# EFR32MG24A020F1536GM40 register map
Vendor: Silicon Labs; Series: EFR32; File version: B
Registers are 32-bit, read-write, reset 0x0 unless marked. A register's access mark holds for its fields unless they carry their own. Offsets are from the block's base; [hi:lo] are bit positions; {n}, {i} and the like mark numbered series; 'fields as' and 'values as' point back to an identical list.

## FRC_S — FRC_S Registers
Base 0xA8004000
Same registers: FRC_NS 0xB8004000
0x00 IPVERSION ro reset 0x3
0x04 EN
  [0] EN — Enable peripheral clock to this module
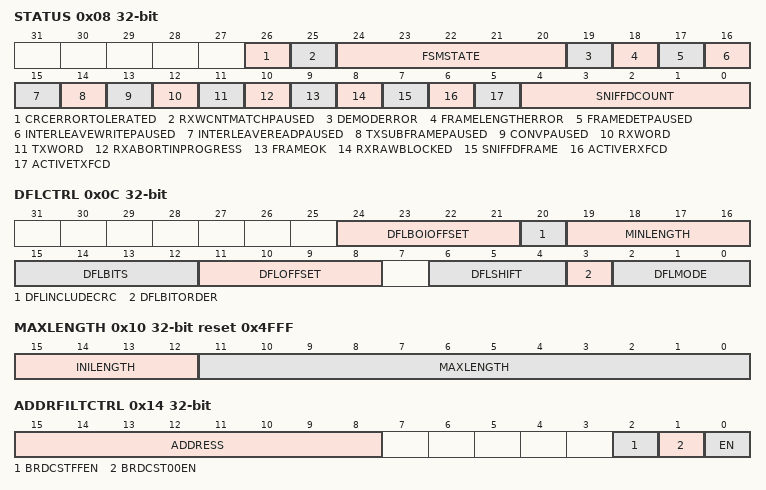
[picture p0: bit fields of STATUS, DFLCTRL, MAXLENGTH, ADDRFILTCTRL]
0x08 STATUS ro
  [26] CRCERRORTOLERATED
  [25] RXWCNTMATCHPAUSED — Nth byte received pause event active
  [24:20] FSMSTATE — FSM state status for srw_frc_interface
    0=IDLE; 1=RX_INIT; 2=RX_DATA; 3=RX_CRC; 4=RX_FCD_UPDATE; 5=RX_DISCARD; 6=RX_TRAIL; 7=RX_DONE; 8=RX_PAUSE_INIT; 9=RX_PAUSED; 10=UNDEFINED1; 11=UNDEFINED2; 12=RX_CRC_ZEROCHECK; 13=RX_SUP; 14=RX_WAITEOF; 15=UNDEFINED3; 16=TX_INIT; 17=TX_DATA; 18=TX_CRC; 19=TX_FCD_UPDATE; 20=TX_TRAIL; 21=TX_FLUSH; 22=TX_DONE; 23=TX_DONE_WAIT; 24=TX_RAW; 25=TX_PAUSEFLUSH
  [19] DEMODERROR — Demod Error in RX
  [18] FRAMELENGTHERROR — Frame Length Error for RX and TX
  [17] FRAMEDETPAUSED — Frame detected pause event active
  [16] INTERLEAVEWRITEPAUSED — Interleaver write pause event active
  [15] INTERLEAVEREADPAUSED — Interleaver read pause event active
  [14] TXSUBFRAMEPAUSED — Transmit subframe pause event active
  [13] CONVPAUSED — Convolutional coder pause event active
  [12] RXWORD — Receive Word Flag
  [11] TXWORD — Transmit Word Flag
  [10] RXABORTINPROGRESS — Receive aborted in progress status flag
  [9] FRAMEOK — Frame valid
  [8] RXRAWBLOCKED — Receiver raw trigger block is active
  [7] SNIFFDFRAME — Sniffer data frame active status
  [6] ACTIVERXFCD — Active Receive Frame Descriptor
    0=FCD2 (FCD2 is active); 1=FCD3 (FCD3 is active)
  [5] ACTIVETXFCD — Active Transmit Frame Descriptor
    0=FCD0 (FCD0 is active); 1=FCD1 (FCD1 is active)
  [4:0] SNIFFDCOUNT — Sniffer data count
0x0C DFLCTRL
  [24:21] DFLBOIOFFSET — Length Field Offset Value
  [20] DFLINCLUDECRC — Length field includes CRC values or not
    0=The CRC values are not included in the frame length; 1=The CRC values are included in the frame length
  [19:16] MINLENGTH — Minimum decoded length
  [15:12] DFLBITS — Length field number of bits
  [11:8] DFLOFFSET — Length Field Offset Value
  [6:4] DFLSHIFT — Dynamic Frame Length bitshift
  [3] DFLBITORDER — Dynamic Frame Length Bit order
    0=NORMAL (Bit ordering is defined by the BITORDER field); 1=REVERSE (Bit ordering is reversed, compared to what is defined by the BITORDER field)
  [2:0] DFLMODE — Dynamic Frame Length Mode
    0=DISABLE (Dynamic Frame Length support is disabled, and the frame length is controlled by writing directly to the FRAMELENGTH field); 1=SINGLEBYTE (Dynamic Frame Length is enabled and located in a single byte over air. This byte is loaded into the least significant byte of the extracted length field); 2=SINGLEBYTEMSB (Dynamic Frame Length is enabled and located in a single byte over air. This byte is loaded into the most significant byte of the extracted length field); 3=DUALBYTELSBFIRST (Dynamic Frame Length is enabled and located in two bytes over air, of which the least significant byte is transferred first); 4=DUALBYTEMSBFIRST (Dynamic Frame Length is enabled and located in two bytes over air, of which the most significant byte is transferred first); 5=INFINITE (Dynamic Frame Length support is disabled, and infinite frame lengths are transmitted and received. RXABORT may be used to abort active receive operations, while the TXDIS command (available in the RAC) may be used to abort active transmit operations.); 6=BLOCKERROR (In transmit mode, the frame length must be written directly to the FRAMELENGTH field. In receive mode, data will be received until a block decoding error is found.)
0x10 MAXLENGTH reset 0x4FFF
  [15:12] INILENGTH — Initial Frame Length Value
  [11:0] MAXLENGTH — Max Frame Length Value
0x14 ADDRFILTCTRL
  [15:8] ADDRESS
  [2] BRDCSTFFEN — Broadcast Address 0xFF Enable
  [1] BRDCST00EN — Broadcast Address 0x00 Enable
  [0] EN — Address Filter Enable
0x18 DATABUFFER
  [7:0] DATABUFFER — Frame Controller data buffer
0x1C WCNT ro
  [11:0] WCNT — Word Counter Value
0x20 WCNTCMP0
  [11:0] FRAMELENGTH — Word Counter Frame Length Value
0x24 WCNTCMP1
  [11:0] LENGTHFIELDLOC — Length field location
0x28 WCNTCMP2
  [11:0] ADDRFIELDLOC — Address field location
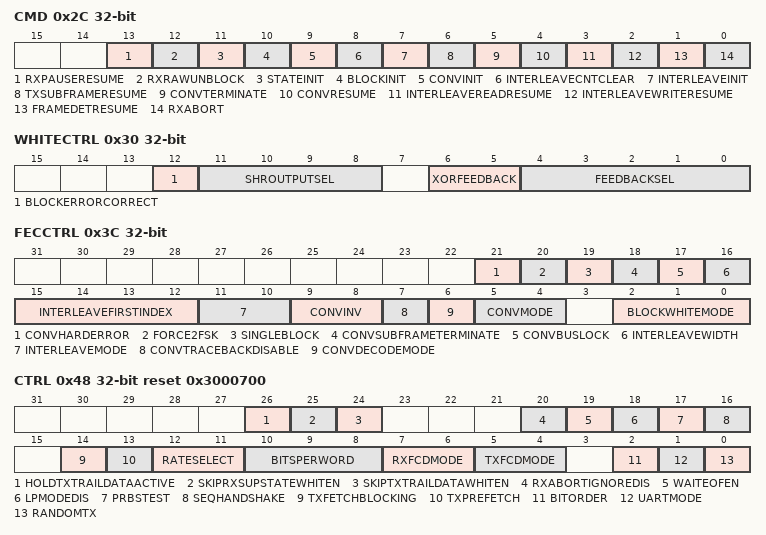
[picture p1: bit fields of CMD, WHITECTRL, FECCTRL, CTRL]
0x2C CMD wo
  [13] RXPAUSERESUME — RX pause on nth byte resume
  [12] RXRAWUNBLOCK — Clear RXRAWBLOCKED status flag
  [11] STATEINIT — FRC State initialize
  [10] BLOCKINIT — Block coder initialize
  [9] CONVINIT — Convolutional coder initialize
  [8] INTERLEAVECNTCLEAR — Interleaver counter clear
  [7] INTERLEAVEINIT — Interleaver initialization
  [6] TXSUBFRAMERESUME
  [5] CONVTERMINATE — Convolutional coder termination
  [4] CONVRESUME — Convolutional coder resume
  [3] INTERLEAVEREADRESUME — Interleaver read resume
  [2] INTERLEAVEWRITERESUME — Interleaver write resume
  [1] FRAMEDETRESUME
  [0] RXABORT
0x30 WHITECTRL
  [12] BLOCKERRORCORRECT — Block Errors Correction enable
    0=Block decoding errors are not corrected, only the BLOCKERR interrupt is set on detection; 1=Block decoding errors are attempted corrected by memory lookup tables. The BLOCKERR interrupt is also set on error detection.
  [11:8] SHROUTPUTSEL — Shift Register Output Selector
  [6:5] XORFEEDBACK — LFSR Feedback XOR setting
    0=DIRECT (The signal defined by FEEDBACKSEL is used directly as Feedback.); 1=XOR (The signal defined by FEEDBACKSEL is XOR'ed with bit 15, and the result is used as Feedback); 2=ZERO (Feedback is set to 0)
  [4:0] FEEDBACKSEL — LFSR Feedback selector
    {v}=BIT{v} (Select bit {v} as feedback) (v=0..15); 16=INPUT (Select data input as feedback); 17=ZERO (Select zero as feedback); 18=ONE (Select one as feedback); 19=TXLASTWORD (In transmit mode, the feedback is one during the last transmit word and zero otherwise. In receive mode, the feedback is always zero.)
0x34 WHITEPOLY
  [15:0] POLY — Whitener Polynomial
0x38 WHITEINIT
  [15:0] WHITEINIT — Whitener Initial Value
0x3C FECCTRL
  [21] CONVHARDERROR — Enable convolutional decoding hard error
    0=Convolutional hard error decoding is disabled; 1=Convolutional hard error decoding is enabled
  [20] FORCE2FSK — Force use of 2-FSK
  [19] SINGLEBLOCK — Single block code per frame
  [18] CONVSUBFRAMETERMINATE — Enable trellis termination for subframes
    0=Trellis termination is applied at the end of the frame; 1=Trellis termination is applied at the end of each subframe and at the end of the frame
  [17] CONVBUSLOCK — Convolutional decoding bus lock
  [16] INTERLEAVEWIDTH — Interleave symbol width.
    0=ONE (Each interleaver element consists of one RF symbol); 1=TWO (Each interleaver element consists of two RF symbols)
  [15:12] INTERLEAVEFIRSTINDEX — 4-bit index of the first interleaver
  [11:10] INTERLEAVEMODE — Interleaver mode.
    0=DISABLE (Interleaving is disabled); 1=ENABLE (Interleaving is enabled); 2=RXBUFFER (No symbol interleaving is performed, but the interleaver data storage is used as a data buffer in receive mode. This may, for instance, be used for receiver pause functionality.); 3=RXTXBUFFER (No symbol interleaving is performed, but the interleaver data storage is used as a data buffer in receive and transmit mode. This may, for instance, be used for receiver and transmitter pause functionality.)
  [9:8] CONVINV — Convolutional code symbol inversion
  [7] CONVTRACEBACKDISABLE — Convolutional traceback disabling
    0=Traceback history is enabled, and convolutional decoding will use RAM to store state information. In receive mode, output from convolutional decoding will be generated after the traceback history has reached a certain level.; 1=Traceback history is disabled, and convolutional decoding will not use RAM to store state information. No trellis termination sequence will be automatically appended to the transmit data. In receive mode, output from convolutional decoding will be generated after every state transition. This will not provide any convolutional decoding gain, but can be used to decode very simple codes without using any RAM memory.
  [6] CONVDECODEMODE — Convolutional decoding mode setting.
    0=SOFT (Use soft decision convolutional decoding, recommended in most cases.); 1=HARD (Use hard decision convolutional decoding.)
  [5:4] CONVMODE — Convolutional Encoder / Decoder mode.
    0=DISABLE (Convolutional encoding / decoding is disabled); 1=CONVOLUTIONAL (Normal convolutional encoding / decoding is enabled); 2=REPEAT (Repeat-mode convolutional encoding / decoding is enabled)
  [2:0] BLOCKWHITEMODE — Block Coder Whitener Mode
    0=DIRECT (The input data is passed directly to the output without any other operations.); 1=WHITE (Data is whitened in TX and de-whitened in RX with the whitener feedback register updated every bit period.); 2=BYTEWHITE (Data is whitened in TX and de-whitened in RX with the whitener feedback register updated every byte period, recommended only for compatibility purposes.); 3=INTERLEAVEDWHITE0 (Data is whitened in TX after symbol interleaving and de-whitened in RX before symbol de-interleaving.); 4=INTERLEAVEDWHITE1 (Data is whitened in TX after symbol interleaving and de-whitened in RX before symbol de-interleaving. The first 16 (if INTERLEAVEWIDTH is 0) or 32 (if INTERLEAVEWIDTH is 1) RF symbols are not whitened or de-whitened.); 5=BLOCKCODEINSERT (Parity bits are added in TX and checked and removed in RX to perform block coding forward error correction (FEC). In transmit mode, the block encoder will insert parity bits between the bit stream provided from the transmit buffer. In receive mode, the block decoder will remove parity bits and they will not further be provided to the receive buffer.); 6=BLOCKCODEREPLACE (Parity bits are added in TX and checked and removed in RX to perform block coding forward error correction (FEC). In transmit mode, the block encoder will replace bits provided by the transmit buffer with parity bits. In receive mode, the block decoder will output both data bits and parity bits to the receive buffer.); 7=BLOCKLOOKUP (A lookup table is used to implement table lookup block coding in TX, and table lookup block decoding in RX.)
0x40 BLOCKRAMADDR reset 0x4000
  [31:2] BLOCKRAMADDR — Block decoding RAM address
0x44 CONVRAMADDR reset 0x4000
  [31:2] CONVRAMADDR — Convolutional decoding RAM address
0x48 CTRL reset 0x3000700
  [26] HOLDTXTRAILDATAACTIVE — Defeat bit to hold txtraildata active
  [25] SKIPRXSUPSTATEWHITEN — RX Supplemental Data Skip Whitening
  [24] SKIPTXTRAILDATAWHITEN — TX Trail Data Skip Whitening
  [20] RXABORTIGNOREDIS — Disable ignoring CMD_RXABORT
  [19] WAITEOFEN — Enable STATE_TX_WAITEOF
  [18] LPMODEDIS — Disable FRC low power
  [17] PRBSTEST — Pseudo-Random Bit Sequence Testmode
  [16] SEQHANDSHAKE — Sequencer data handshake
    0=The sequencer may read transmit or read data through the FRCRD command, but it will not wait for the sequencer to do so before proceeding to parse transmit or receive data; 1=The frame controller will require that the sequencer program uses the FRCRD command to read both transmit and receive data which the frame controller stores in the DATABUFFER register. If data is not read with this field set, the overflow (RXOF) or underflow (TXUF) will be set.
  [14] TXFETCHBLOCKING — Transmit fetch data blocking
  [13] TXPREFETCH — Transmit prefetch data
    0=The frame controller will start preparing transmit data when entering the TX state. This setting may be used in most cases.; 1=The frame controller will start preparing transmit data already in the TXWARM, RX2TX or TX2TX state. This setting must be used to avoid transmit underflow in the cases where no preamble or frame synchronization is inserted by the modulator (i.e. typically when the MODEM control fields TXBASES is zero and SYNCDATA is set).
  [12:11] RATESELECT — MODEM rate select
  [10:8] BITSPERWORD — Bits Per Word, for first word in a frame
  [7:6] RXFCDMODE — RX Frame Control Descriptor Mode
    0=FCDMODE0 (FCD2 is reloaded when SCNT reaches 0); 1=FCDMODE1 (Use FCD2 for the first sub-frame, then switching between FCD2 and FCD3 for following sub-frames); 2=FCDMODE2 (Use FCD2 for the first sub-frame, then FCD3 is used for all following sub-frames); 3=FCDMODE3 (Use alternating FCD2 / FCD3 for each complete frame)
  [5:4] TXFCDMODE — TX Frame Control Descriptor Mode
    0=FCDMODE0 (FCD0 is reloaded when SCNT reaches 0); 1=FCDMODE1 (Use FCD0 for the first sub-frame, then switching between FCD0 and FCD1 for following sub-frames); 2=FCDMODE2 (Use FCD0 for the first sub-frame, then FCD1 is used for all following sub-frames); 3=FCDMODE3 (Use alternating FCD0 / FCD1 for each complete frame)
  [2] BITORDER — Data Bit Order.
    0=LSBFIRST (Least Significant bit in each word is sent/received first.); 1=MSBFIRST (Most Significant bit in each word is sent/received first.)
  [1] UARTMODE — Data Uart Mode
  [0] RANDOMTX — Random TX Mode
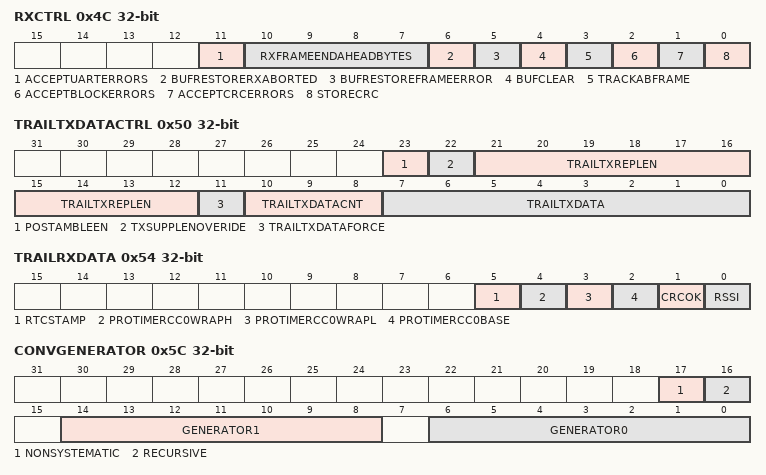
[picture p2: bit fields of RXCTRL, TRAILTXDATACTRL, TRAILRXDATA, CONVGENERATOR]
0x4C RXCTRL
  [11] ACCEPTUARTERRORS — Accept UART Start/Stop bit Errors.
  [10:7] RXFRAMEENDAHEADBYTES — RX frame almost end of packet timing
  [6] BUFRESTORERXABORTED — Buffer restore on RXABORTED
  [5] BUFRESTOREFRAMEERROR — Buffer restore on frame error
  [4] BUFCLEAR — Buffer Clear
  [3] TRACKABFRAME — Track Aborted RX Frame
    0=When a frame abort is triggered, the frame reception is immediately aborted, the RXABORTED interrupt flag is set, and the receiver may start searching for a new frame; 1=When a frame abort is triggered, the receiver is still enabled for the duration of the frame (as defined by the frame length), but no data output is generated. Only when the complete frame is received, the RXABORTED interrupt flag is set and a new frame reception may begin. This mode may, for instance, be used to avoid finding a new FRAMEDET event inside the payload data of a discarded frame.
  [2] ACCEPTBLOCKERRORS — Accept Block Decoding Errors.
    0=REJECT (Frame reception will be stopped when a block decoding error is found.); 1=ACCEPT (Frame reception will continue even in the case of a block decoding error.)
  [1] ACCEPTCRCERRORS
    0=REJECT (Frames with one or more detected CRC errors will be cleared from the receiver buffer.); 1=ACCEPT (Frames will always be written to the receive buffer, regardless of CRC errors.)
  [0] STORECRC — Store CRC value.
0x50 TRAILTXDATACTRL
  [23] POSTAMBLEEN — WMBUS T mode postamble enable
  [22] TXSUPPLENOVERIDE — TX Sup Len Override
  [21:12] TRAILTXREPLEN — Trailing Data Repeat Length
  [11] TRAILTXDATAFORCE — Force trailing TX data insertion
    0=Trailing data in transmit is only applied in order to fill up an integer number of block coding and interleaver buffers. If block coding and interleaving is not used, no trailing data is transmitted.; 1=The number of bits defined by TRAILTXDATACNT is always appended to the transmit data, in addition to the necessary bits to fill up an integer number of block coding and interleaver buffers
  [10:8] TRAILTXDATACNT — Trailing data bit count
  [7:0] TRAILTXDATA — Trailing Data value
0x54 TRAILRXDATA
  [5] RTCSTAMP — RTCC Time Stamp
  [4] PROTIMERCC0WRAPH — PROTIMER Capture Compare channel 0 WrapH
  [3] PROTIMERCC0WRAPL — PROTIMER Capture Compare channel 0 WrapL
  [2] PROTIMERCC0BASE — PROTIMER Capture Compare channel 0 Base
  [1] CRCOK — Append CRC OK Indicator
  [0] RSSI — Append RSSI
0x58 SCNT ro
  [7:0] SCNT — Sub-Frame Counter Value
0x5C CONVGENERATOR
  [17] NONSYSTEMATIC — Non systematic recursive code
    0=The recursive code is systematic; 1=The recursive code is not systematic
  [16] RECURSIVE — Convolutional encoding
    0=Non-recursive convolutional coding is used; 1=Recursive convolutional coding is used
  [14:8] GENERATOR1 — Output 1 Generator Polynomial
  [6:0] GENERATOR0 — Output 0 Generator Polynomial
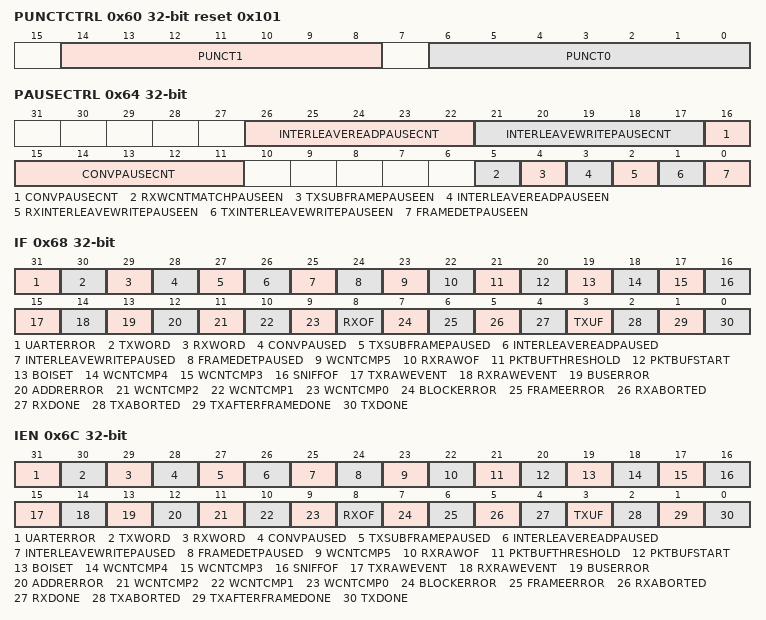
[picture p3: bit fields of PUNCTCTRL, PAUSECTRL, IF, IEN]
0x60 PUNCTCTRL reset 0x101
  [14:8] PUNCT1 — Puncturing Matrix Row for Output 1
  [6:0] PUNCT0 — Puncturing Matrix Row for Output 0
0x64 PAUSECTRL
  [26:22] INTERLEAVEREADPAUSECNT — Interleaver read pause count
  [21:17] INTERLEAVEWRITEPAUSECNT — Interleaver write pause count
  [16:11] CONVPAUSECNT — Convolutional decoder pause setting
  [5] RXWCNTMATCHPAUSEEN — Receive wcnt match pause enable
  [4] TXSUBFRAMEPAUSEEN — Transmit subframe pause enable
  [3] INTERLEAVEREADPAUSEEN — Interleaver read pause enable
  [2] RXINTERLEAVEWRITEPAUSEEN — Receive interleaver write pause enable
  [1] TXINTERLEAVEWRITEPAUSEEN — Transmit interleaver write pause enable
  [0] FRAMEDETPAUSEEN — Frame detect pause enable
0x68 IF
  [31] UARTERROR — Uart Error Interrupt Flag
  [30] TXWORD — Transmit Word Interrupt Flag
  [29] RXWORD — Receive Word Interrupt Flag
  [28] CONVPAUSED — Convolutional coder pause event active
  [27] TXSUBFRAMEPAUSED — Transmit subframe pause event active
  [26] INTERLEAVEREADPAUSED — Interleaver read pause event active
  [25] INTERLEAVEWRITEPAUSED — Interleaver write pause event active
  [24] FRAMEDETPAUSED — Frame detected pause event active
  [23] WCNTCMP5 — Word Counter Compare 5 Event
  [22] RXRAWOF — RX raw FIFO overflow
  [21] PKTBUFTHRESHOLD — Packet Buffer Threshold
  [20] PKTBUFSTART — Packet Buffer Start
  [19] BOISET
  [18] WCNTCMP4 — Word Counter Compare 4 Event
  [17] WCNTCMP3 — Word Counter Compare 3 Event
  [16] SNIFFOF — Data sniffer overflow
  [15] TXRAWEVENT — Transmit raw data event
  [14] RXRAWEVENT — Receiver raw data event
  [13] BUSERROR — A bus error event occurred
  [12] ADDRERROR — Receive address error event
  [11] WCNTCMP2 — Word Counter Compare 2 Event
  [10] WCNTCMP1 — Word Counter Compare 1 Event
  [9] WCNTCMP0 — Word Counter Compare 0 Event
  [8] RXOF — Receive Overflow Interrupt Flag
  [7] BLOCKERROR — Block Error Interrupt Flag
  [6] FRAMEERROR — Frame Error Interrupt Flag
  [5] RXABORTED — RX Aborted Interrupt Flag
  [4] RXDONE — RX Done Interrupt Flag
  [3] TXUF — Transmit Underflow Interrupt Flag
  [2] TXABORTED — Transmit Aborted Interrupt Flag
  [1] TXAFTERFRAMEDONE — TX after frame Done Interrupt Flag
  [0] TXDONE — TX Done Interrupt Flag
0x6C IEN
  [31] UARTERROR — UART Error Interrupt Enable
  [30] TXWORD — Transmit Word Interrupt Enable
  [29] RXWORD — Receive Word Interrupt Enable
  [28] CONVPAUSED — Convolutional coder pause event enable
  [27] TXSUBFRAMEPAUSED — Transmit subframe pause event enable
  [26] INTERLEAVEREADPAUSED — Interleaver read pause event enable
  [25] INTERLEAVEWRITEPAUSED — Interleaver write pause event enable
  [24] FRAMEDETPAUSED — Frame detected pause event enable
  [23] WCNTCMP5 — Word Counter Compare 5 Enable
  [22] RXRAWOF — RXRAWOF Enable
  [21] PKTBUFTHRESHOLD — PKTBUFTHRESHOLD Enable
  [20] PKTBUFSTART — PKTBUFSTART Enable
  [19] BOISET
  [18] WCNTCMP4 — Word Counter Compare 4 Enable
  [17] WCNTCMP3 — Word Counter Compare 3 Enable
  [16] SNIFFOF — Data sniffer overflow enable
  [15] TXRAWEVENT — Transmit raw data enable
  [14] RXRAWEVENT — Receiver raw data enable
  [13] BUSERROR — Bus error enable
  [12] ADDRERROR — Receive address error enable
  [11] WCNTCMP2 — Word Counter Compare 2 Enable
  [10] WCNTCMP1 — Word Counter Compare 1 Enable
  [9] WCNTCMP0 — Word Counter Compare 0 Enable
  [8] RXOF — Receive Overflow Interrupt Enable
  [7] BLOCKERROR — Block Error Interrupt Enable
  [6] FRAMEERROR — Frame Error Interrupt Enable
  [5] RXABORTED — RX Aborted Interrupt Enable
  [4] RXDONE — RX Done Interrupt Enable
  [3] TXUF — Transmit Underflow Interrupt Enable
  [2] TXABORTED — Transmit Aborted Interrupt Enable
  [1] TXAFTERFRAMEDONE — TX after frame Done Interrupt Enable
  [0] TXDONE — TX Done Interrupt Enable
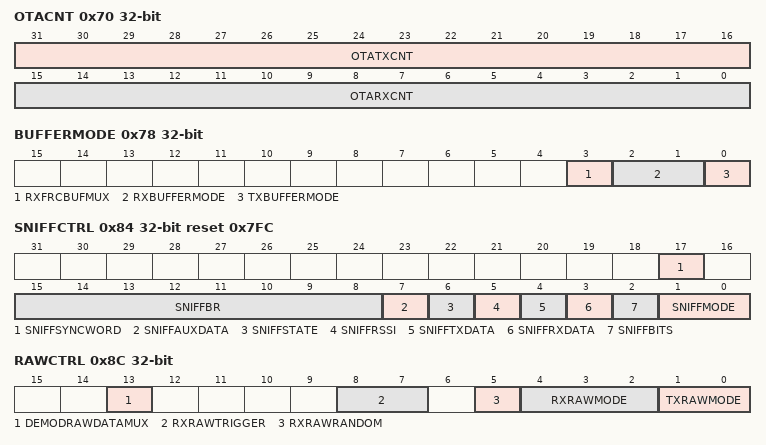
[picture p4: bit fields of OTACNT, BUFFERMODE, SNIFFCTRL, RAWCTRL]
0x70 OTACNT ro
  [31:16] OTATXCNT — OTA TX bit counter
  [15:0] OTARXCNT — OTA RX bit counter
0x78 BUFFERMODE
  [3] RXFRCBUFMUX — RX FRC Buffer Mux
  [2:1] RXBUFFERMODE — Receive Buffer Mode
    0=BUFC (The Frame Controller write data to the Buffer Controller (BUFC) in receive mode.); 1=REGISTER (The Frame Controller does not write data to the Buffer Controller in receive mode. Instead, data must be read from the DATABUFFER register when the RXWORD interrupt flag is set.); 2=DISABLE (The Frame Controller will not output demodulated data. This mode can, for instance, be used together with storing RAW frame data.)
  [0] TXBUFFERMODE — Transmit Buffer Mode
    0=BUFC (The Frame Controller fetches data from the Buffer Controller (BUFC) in transmit mode.); 1=REGISTER (The Frame Controller does not fetch data from the Buffer Controller in transmit mode. Instead, data must be written to the DATABUFFER register when the TXWORD interrupt flag is set.)
0x84 SNIFFCTRL reset 0x7FC
  [17] SNIFFSYNCWORD — Sniffer baudrate setting
  [15:8] SNIFFBR — Sniffer baudrate setting
  [7] SNIFFAUXDATA — Enable sniffing of auxiliary data
  [6] SNIFFSTATE — Enable sniffing of state information
  [5] SNIFFRSSI — Enable sniffing of RSSI
  [4] SNIFFTXDATA — Enable sniffing of transmitted data.
  [3] SNIFFRXDATA — Enable sniffing of received data.
  [2] SNIFFBITS — Data sniff data bits
    0=EIGHT (Each sniffer output word contains 8 data bits); 1=NINE (Each sniffer output word contains 9 data bits)
  [1:0] SNIFFMODE — Data Sniff Mode
    0=OFF (FRC Packet Sniffer mode is disabled); 1=UART (UART encoded data is transmitted on the DOUT pin.); 2=SPI (SPI data is transmitted on the DOUT pin and a data clock is output to the DCLK pin.)
0x88 AUXDATA wo
  [8:0] AUXDATA — Auxiliary sniffer data output
0x8C RAWCTRL
  [13] DEMODRAWDATAMUX — Raw data mux control
    0=DEMODRAWDATASEL (RAW data is selected using modem register DEMODRAWDATASEL.); 1=DEMODRAWDATASEL2 (RAW data is selected using modem register DEMODRAWDATASEL2.)
  [8:7] RXRAWTRIGGER — Receiver raw data trigger setting
    0=IMMEDIATE (RAW data storage is triggered immediately when demodulator is enabled.); 1=PRS (RAW data storage is triggered by the selected RXRAWPRSSEL PRS channel.); 2=INTERNALSIG (RAW data storage is triggered by an internal signal)
  [5] RXRAWRANDOM — Receive raw data random number generator
  [4:2] RXRAWMODE — Receiver raw data mode
    0=DISABLE (RAW receive mode is disabled); 1=SINGLEITEM (RAW receive mode is enabled, fetching a single item which is stored in the RXRAWDATA register. A new item is fetched when the RXRAWBLOCKED flag is cleared. In this mode, the flag is cleared automatically when RXRAWDATA is read.); 2=SINGLEBUFFER (RAW receive mode is enabled, fetching multiple items which are stored to RAM. The RXRAWBLOCKED flag must be cleared in order to start raw data reception.); 3=SINGLEBUFFERFRAME (This mode is identical to the SINGLEBUFFER mode, except that the FRC will treat the end of the filled buffer as the end of a frame reception (i.e. also trigger the RXDONE interrupt and signal to the RAC that frame reception is complete.)); 4=REPEATBUFFER (RAW receive mode is enabled, fetching multiple items which are stored to RAM. The RXRAWBLOCKED flag must be cleared in order to start raw data reception.)
  [1:0] TXRAWMODE — Transmitter raw data mode
    0=DISABLE (RAW transmit mode is disabled); 1=SINGLEBUFFER (RAW transmit mode is enabled, transmitting the configured raw data (fetched from RAM) once before transmit is completed.); 2=REPEATBUFFER (RAW transmit mode is enabled, transmitting the configured raw data (fetched from RAM) repeatedly until the transmitter is disabled.)
0x90 RXRAWDATA ro
  [31:0] RXRAWDATA — Receiver RAW data register
0x94 PAUSEDATA ro
  [31:0] PAUSEDATA — Receiver pause data register
0x98 LIKELYCONVSTATE ro
  [5:0] LIKELYCONVSTATE — Most likely convolutional decoder state
0x9C INTELEMENTNEXT ro
  [7:0] INTELEMENTNEXT — Interleaver element value
0xA0 INTWRITEPOINT
  [4:0] INTWRITEPOINT — Interleaver buffer write pointer
0xA4 INTREADPOINT
  [4:0] INTREADPOINT — Interleaver buffer read pointer
0xA8 AUTOCG
  [15:0] AUTOCGEN — Automatic clock gate enable
0xAC CGCLKSTOP
  [15:0] FORCEOFF
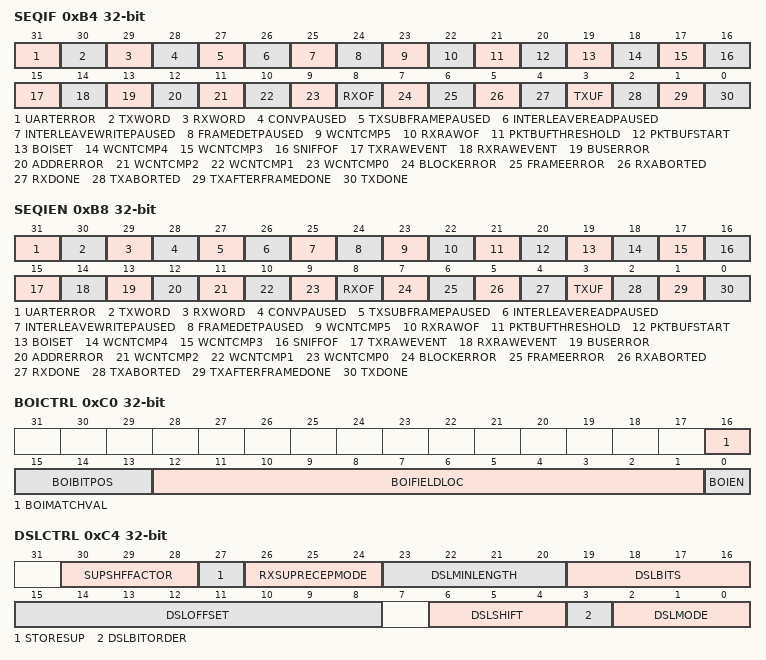
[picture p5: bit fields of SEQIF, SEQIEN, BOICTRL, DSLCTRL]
0xB4 SEQIF
  [31] UARTERROR — Uart Error Interrupt Flag
  [30] TXWORD — Transmit Word Interrupt Flag
  [29] RXWORD — Receive Word Interrupt Flag
  [28] CONVPAUSED — Convolutional coder pause event active
  [27] TXSUBFRAMEPAUSED — Transmit subframe pause event active
  [26] INTERLEAVEREADPAUSED — Interleaver read pause event active
  [25] INTERLEAVEWRITEPAUSED — Interleaver write pause event active
  [24] FRAMEDETPAUSED — Frame detected pause event active
  [23] WCNTCMP5 — Word Counter Compare 5 Event
  [22] RXRAWOF — RX raw FIFO overflow
  [21] PKTBUFTHRESHOLD — Packet Buffer Threshold
  [20] PKTBUFSTART — Packet Buffer Start
  [19] BOISET — BOISET Event
  [18] WCNTCMP4 — Word Counter Compare 4 Event
  [17] WCNTCMP3 — Word Counter Compare 3 Event
  [16] SNIFFOF — Data sniffer overflow
  [15] TXRAWEVENT — Transmit raw data event
  [14] RXRAWEVENT — Receiver raw data event
  [13] BUSERROR — A bus error event occurred
  [12] ADDRERROR — Receive address error event
  [11] WCNTCMP2 — Word Counter Compare 2 Event
  [10] WCNTCMP1 — Word Counter Compare 1 Event
  [9] WCNTCMP0 — Word Counter Compare 0 Event
  [8] RXOF — Receive Overflow Interrupt Flag
  [7] BLOCKERROR — Block Error Interrupt Flag
  [6] FRAMEERROR — Frame Error Interrupt Flag
  [5] RXABORTED — RX Aborted Interrupt Flag
  [4] RXDONE — RX Done Interrupt Flag
  [3] TXUF — Transmit Underflow Interrupt Flag
  [2] TXABORTED — Transmit Aborted Interrupt Flag
  [1] TXAFTERFRAMEDONE — TX after frame Done Interrupt Flag
  [0] TXDONE — TX Done Interrupt Flag
0xB8 SEQIEN
  [31] UARTERROR — UART Error Interrupt Enable
  [30] TXWORD — Transmit Word Interrupt Enable
  [29] RXWORD — Receive Word Interrupt Enable
  [28] CONVPAUSED — Convolutional coder pause event enable
  [27] TXSUBFRAMEPAUSED — Transmit subframe pause event enable
  [26] INTERLEAVEREADPAUSED — Interleaver read pause event enable
  [25] INTERLEAVEWRITEPAUSED — Interleaver write pause event enable
  [24] FRAMEDETPAUSED — Frame detected pause event enable
  [23] WCNTCMP5 — Word Counter Compare 5 Enable
  [22] RXRAWOF — RXRAWOF Enable
  [21] PKTBUFTHRESHOLD — PKTBUFTHRESHOLD Enable
  [20] PKTBUFSTART — PKTBUFSTART Enable
  [19] BOISET — Word Counter Compare 2 Enable
  [18] WCNTCMP4 — Word Counter Compare 4 Enable
  [17] WCNTCMP3 — Word Counter Compare 3 Enable
  [16] SNIFFOF — Data sniffer overflow enable
  [15] TXRAWEVENT — Transmit raw data enable
  [14] RXRAWEVENT — Receiver raw data enable
  [13] BUSERROR — Bus error enable
  [12] ADDRERROR — Receive address error enable
  [11] WCNTCMP2 — Word Counter Compare 2 Enable
  [10] WCNTCMP1 — Word Counter Compare 1 Enable
  [9] WCNTCMP0 — Word Counter Compare 0 Enable
  [8] RXOF — Receive Overflow Interrupt Enable
  [7] BLOCKERROR — Block Error Interrupt Enable
  [6] FRAMEERROR — Frame Error Interrupt Enable
  [5] RXABORTED — RX Aborted Interrupt Enable
  [4] RXDONE — RX Done Interrupt Enable
  [3] TXUF — Transmit Underflow Interrupt Enable
  [2] TXABORTED — Transmit Aborted Interrupt Enable
  [1] TXAFTERFRAMEDONE — TX after frame Done Interrupt Enable
  [0] TXDONE — TX Done Interrupt Enable
0xBC WCNTCMP3
  [11:0] SUPPLENFIELDLOC — Sup Length field location
0xC0 BOICTRL
  [16] BOIMATCHVAL — BOI match value
  [15:13] BOIBITPOS — BOI bit position
  [12:1] BOIFIELDLOC — BOI field location
  [0] BOIEN
0xC4 DSLCTRL
  [30:28] SUPSHFFACTOR — Supp Shift factor
  [27] STORESUP — Store SUPP in BUFC
  [26:24] RXSUPRECEPMODE — RX Supplement Reception Mode
    0=NOSUP (Do not receive SUP); 1=BOIDSLBASED (Receive SUP based on BOI and fetch SUPLEN from DSL setting); 2=BOIFIXEDSLBASED (Receive SUP based on BOI and fetch SUPLEN from WCNTCMP4); 3=DSLBASED (Receive SUP based irrespective of BOI and fetch SUPLEN from DSL setting); 4=FIXEDSLBASED (Receive SUP based irrespective of BOI and fetch SUPLEN from WCNTCMP4 setting)
  [23:20] DSLMINLENGTH — Minimum decoded length
  [19:16] DSLBITS — Length field number of bits
  [15:8] DSLOFFSET — Length Field Offset Value
  [6:4] DSLSHIFT — Dynamic Frame Length bitshift
  [3] DSLBITORDER — Dynamic Frame Length Bit order
    values as DFLCTRL.DFLBITORDER
  [2:0] DSLMODE — Dynamic Frame Length Mode
    values as DFLCTRL.DFLMODE
0xC8 WCNTCMP4
  [11:0] SUPPLENGTH — Supp Length Value
0xCC WCNTCMP5
  [11:0] RXPAUSELOC — RX pause location
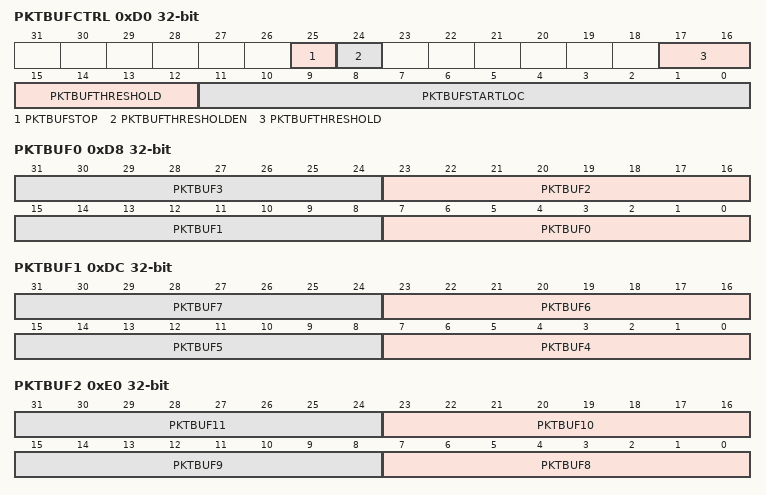
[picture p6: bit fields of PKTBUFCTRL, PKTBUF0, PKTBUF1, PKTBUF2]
0xD0 PKTBUFCTRL
  [25] PKTBUFSTOP wo — Packet Buffer stop receiving command
  [24] PKTBUFTHRESHOLDEN — Packet Buffer Threshold Enable
  [17:12] PKTBUFTHRESHOLD — Packet Buffer Threshold
  [11:0] PKTBUFSTARTLOC — Packet Buffer Start Address
0xD4 PKTBUFSTATUS ro
  [5:0] PKTBUFCOUNT — Packet Buffer Count
0xD8 PKTBUF0 ro
  [8n+7:8n] PKTBUF{n} (n=0..3) — Packet Capture Buffer
0xDC PKTBUF1 ro
  [8n-25:8n-32] PKTBUF{n} (n=4..7) — Packet Capture Buffer
0xE0 PKTBUF2 ro
  [8n-57:8n-64] PKTBUF{n} (n=8..11) — Packet Capture Buffer
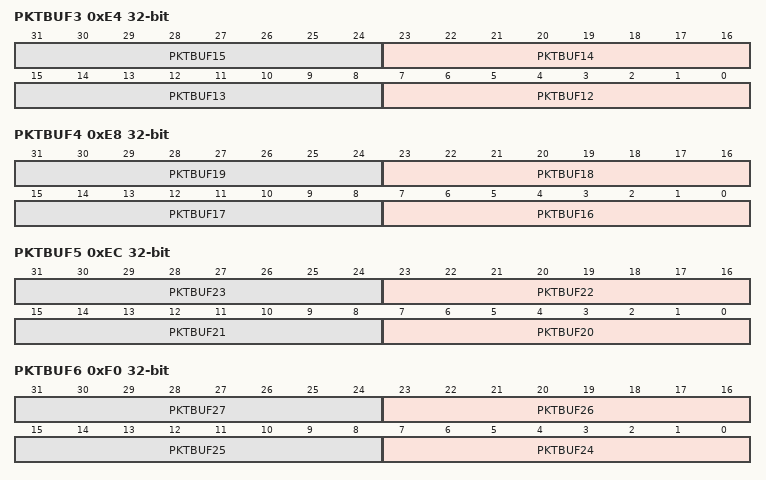
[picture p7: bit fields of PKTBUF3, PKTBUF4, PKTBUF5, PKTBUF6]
0xE4 PKTBUF3 ro
  [8n-89:8n-96] PKTBUF{n} (n=12..15) — Packet Capture Buffer
0xE8 PKTBUF4 ro
  [8n-121:8n-128] PKTBUF{n} (n=16..19) — Packet Capture Buffer
0xEC PKTBUF5 ro
  [8n-153:8n-160] PKTBUF{n} (n=20..23) — Packet Capture Buffer
0xF0 PKTBUF6 ro
  [8n-185:8n-192] PKTBUF{n} (n=24..27) — Packet Capture Buffer
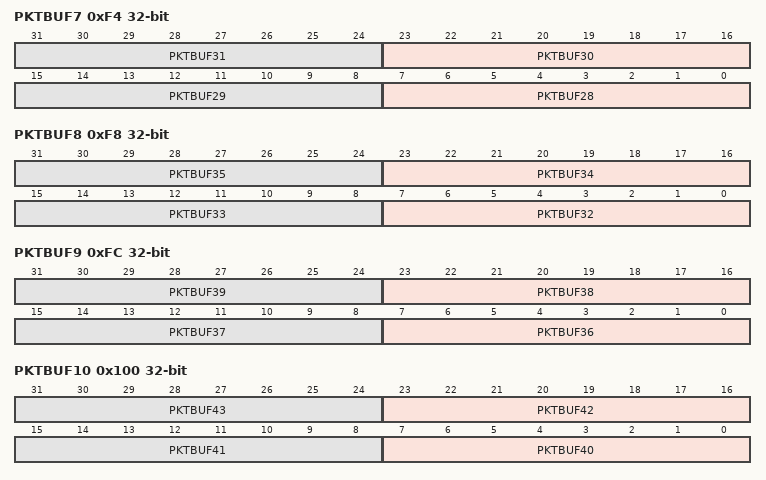
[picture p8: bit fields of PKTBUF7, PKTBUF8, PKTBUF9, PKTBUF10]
0xF4 PKTBUF7 ro
  [8n-217:8n-224] PKTBUF{n} (n=28..31) — Packet Capture Buffer
0xF8 PKTBUF8 ro
  [8n-249:8n-256] PKTBUF{n} (n=32..35) — Packet Capture Buffer
0xFC PKTBUF9 ro
  [8n-281:8n-288] PKTBUF{n} (n=36..39) — Packet Capture Buffer
0x100 PKTBUF10 ro
  [8n-313:8n-320] PKTBUF{n} (n=40..43) — Packet Capture Buffer
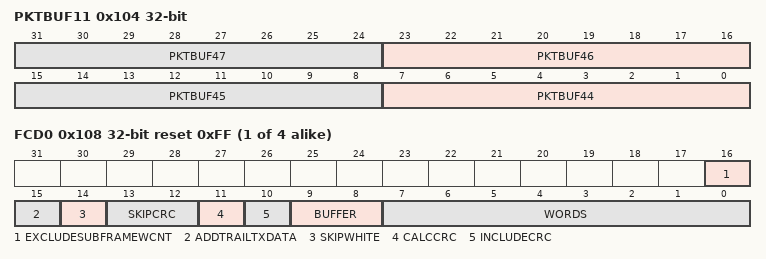
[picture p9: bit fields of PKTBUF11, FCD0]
0x104 PKTBUF11 ro
  [8n-345:8n-352] PKTBUF{n} (n=44..47) — Packet Capture Buffer
{0x108+4i} FCD{i} reset 0xFF (i=0..3)
  [16] EXCLUDESUBFRAMEWCNT — Exclude subframe from WCNT
  [15] ADDTRAILTXDATA — Add trailing TX data in this subframe
  [14] SKIPWHITE — Skip data whitening in this subframe
  [13:12] SKIPCRC — Skip First Words in CRC Calculation
  [11] CALCCRC — Calculate CRC
  [10] INCLUDECRC
  [9:8] BUFFER — Buffer to Access
  [7:0] WORDS — No of Words in sub-frame
{0x140+4i} INTELEMENT{i} ro (i=0..15)
  [7:0] INTELEMENT — Interleaver element data
0x180 AHBCONFIG reset 0x1
  [0] AHBHPROTBUFFERABLE — Bufferable Privileged data for AHB
